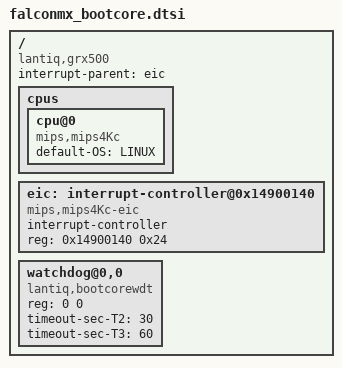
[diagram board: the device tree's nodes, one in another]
/ {
	#address-cells = <1>;
	#size-cells = <1>;
	compatible = "lantiq,grx500";  
    interrupt-parent = <&eic>;

	cpus {
		cpu@0 {
			compatible = "mips,mips4Kc";
			default-OS = "LINUX";
		};
	
	};

    eic: interrupt-controller@0x14900140 {
        compatible = "mips,mips4Kc-eic";
        #interrupt-cells = <1>;
        #address-cells = <0>;
        interrupt-controller;
        reg = <0x14900140 0x24>;
    };

	watchdog@0,0 {
		compatible = "lantiq,bootcorewdt","lantiq, wdt-bootcore-xrx500"; 
		reg = <0 0>;
		timeout-sec-T2 = <30>;
		timeout-sec-T3 = <60>;
	};

};
